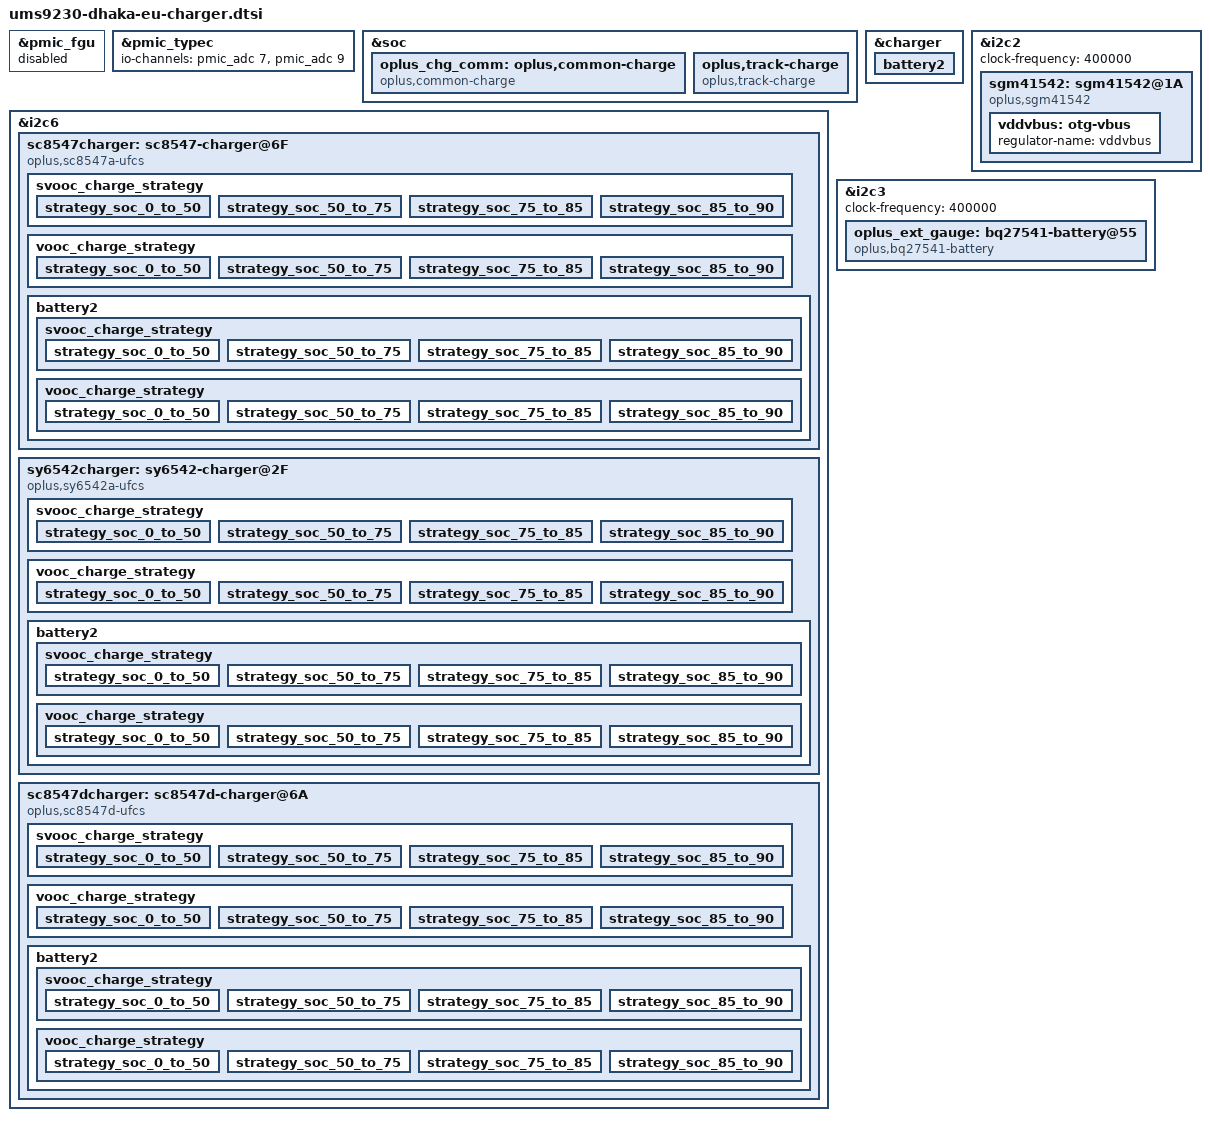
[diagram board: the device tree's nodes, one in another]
// SPDX-License-Identifier: GPL-2.0-only
/*
* Copyright (C) 2018-2020 Oplus. All rights reserved.
*/

&pmic_fgu {
	status = "disabled";
	//charger = <&sgm41542>;
	FUELGAGUE_APPLY = <(0)>;
	BATT_ID_FAST_CHECK = <(3)>;
	Enable_Is_Force_Full = <(1)>;
	sprd,calib-resistance-micro-ohms = <5000>;
	sprd,comp-resistance-mohm = <4>;
};

&pmic_typec {
	status = "okay";
	io-channels = <&pmic_adc 7>, <&pmic_adc 9>;
	io-channel-names = "cc1", "cc2";
};

&soc {
 	oplus_chg_comm: oplus,common-charge {
 		status = "ok";
 		compatible = "oplus,common-charge";

 		//io-channels = <&pmk8350_vadc PM8350_ADC7_AMUX_THM3_100K_PU>;
 		//io-channel-names = "pm8350_hot_pocket_therm";

 		//oplus,skin_temp_chan = "pm8350_hot_pocket_therm";

 		oplus,check-batt-full-by-sw;
 		oplus,fv-offset-voltage-mv = <32>;
 		oplus,sw-iterm-ma = <115>;
 		oplus,full-count-sw-num = <2>;
 		oplus,batt-uv-mv = <2500>;
 		oplus,batt-ov-mv = <4950>;
 		oplus,batt-oc-ma = <6500>;
 		oplus,batt-ovd-mv = <1000>;
 		oplus,batt-curr-limit-thr-mv = <4180>;

 		oplus,batt-them-thr = <(-20) 0 50 120 400 450 530>;//tbat
 		oplus,vbatmax-mv = <0 4470 4470 4470 4470 4470 4130 0>;//fv
 		oplus,vbatmax-mv_4p48 = <0 4470 4470 4470 4470 4470 4130 0>;//fv for 4p48 batt
 		oplus,ffc-temp-thr = <120 350 450>;
 		oplus,usb-ffc-step-max = <1>;
 		oplus,usb-ffc-fv-mv = <4500>;
 		oplus,usb-ffc-fv-cutoff-mv = <4600>;
 		oplus,usb-ffc-fcc-ma = <350 400>;
 		oplus,usb-ffc-fcc-cutoff-ma = <300 350>;
 	};
	oplus,track-charge {
		compatible = "oplus,track-charge";
		track,fast_chg_break_t_thd = <1000>;
		track,general_chg_break_t_thd = <200>;
		track,voocphy_type = <2>;
		track,wired_max_power = <45000>;
		track,wired_fast_chg_scheme = <4>;
		track,gauge_status_ctrl;
		track,nominal_qmax1 = <5166>;
		track,nominal_fcc1 = <4700>;
		track,external_gauge_num = <1>;
	};
 };
&charger {
	io-channels = <&pmic_adc 6>, <&pmic_adc 4>, <&pmic_adc 14>;
	io-channel-names = "usb_temp_v_l", "usb_temp_v_r", "charge_vbus";
	//for oplus chg framework:
	qcom,pd_input_current_charger_ma = <3000>;
	qcom,qc_input_current_charger_ma = <1500>;
	qcom,input_current_charger_ma = <2000>;
	qcom,input_current_usb_ma = <500>;
	qcom,input_current_cdp_ma = <1500>;
	qcom,input_current_camera_ma = <1200>;
	qcom,input_current_calling_ma = <1500>;

	qcom,led_warm_bat_decidegc = <350>;
	qcom,led_high_bat_decidegc = <370>;
	qcom,input_current_led_ma = <1200>;
	qcom,input_current_led_ma_high = <1200>;
	qcom,input_current_led_ma_warm = <1500>;
	qcom,input_current_led_ma_normal = <3000>;
	qcom,input_current_led_ma_forcmcc = <500>;
	qcom,input_current_led_ma_limit_high = <1200>;

	qcom,vooc_temp_bat_normal_decidegc = <350>;
	qcom,vooc_temp_bat_warm_decidegc = <370>;
	qcom,vooc_temp_bat_hot_decidegc = <440>;
	qcom,input_current_vooc_led_ma_high = <1200>;
	qcom,input_current_vooc_led_ma_warm = <1800>;
	qcom,input_current_vooc_led_ma_normal = <3600>;
	qcom,input_current_vooc_ma_normal = <3600>;
	qcom,input_current_vooc_ma_warm = <3200>;
	qcom,input_current_vooc_ma_high = <2200>;

	qcom,overtemp_bat_decidegc = <350>;
	qcom,iterm_disabled = <0>;
	//sw_full_count = <25>;
	qcom,iterm_ma = <302>;
	qcom,recharge-mv = <100>;

	qcom,batt_capacity_mah = <6000>; /*typical capacity*/
	//qcom,batt_capacity_mah = <4870>; /*rated capacity*/
	qcom,usb_high_than_bat_decidegc = <168>;

	qcom,removed_bat_decidegc = <390>;  /* < -39C */

	qcom,cold_bat_decidegc = <100>;  /* -10C ~ 0C */
	qcom,temp_cold_vfloat_mv = <4464>;
	qcom,temp_freeze_fastchg_current_ma_high = <1166>;
	qcom,temp_freeze_fastchg_current_ma_low = <874>;
	qcom,temp_freeze_fastchg_current_ma = <1166>;
	qcom,temp_cold_fastchg_current_ma_high = <1166>;
	qcom,temp_cold_fastchg_current_ma_low = <874>;
	qcom,temp_cold_fastchg_current_ma = <1166>;

	qcom,little_cold_bat_decidegc = <0>;    /* 0C ~ 5C */
	qcom,temp_little_cold_vfloat_mv = <4464>;
	qcom,temp_little_cold_fastchg_current_ma_high = <2200>;
	qcom,temp_little_cold_fastchg_current_ma_low = <2200>;
	qcom,temp_little_cold_fastchg_current_ma = <2200>;
	qcom,qc_temp_little_cold_fastchg_current_ma_high = <800>;
	qcom,qc_temp_little_cold_fastchg_current_ma_low = <2623>;
	qcom,pd_temp_little_cold_fastchg_current_ma_high = <3000>;
	qcom,pd_temp_little_cold_fastchg_current_ma_low = <2623>;

	qcom,cool_bat_decidegc = <50>;  /* 5C ~ 12C */
	qcom,temp_cool_vfloat_mv = <4464>;
	qcom,temp_cool_fastchg_current_ma_high = <2200>;
	qcom,temp_cool_fastchg_current_ma_low = <2200>;
	qcom,qc_temp_cool_fastchg_current_ma_high = <1600>;
	qcom,qc_temp_cool_fastchg_current_ma_low = <3000>;
	qcom,pd_temp_cool_fastchg_current_ma_high = <3000>;
	qcom,pd_temp_cool_fastchg_current_ma_low = <3000>;

	qcom,little_cool_bat_decidegc = <120>;  /* 12C ~ 16C */
	qcom,temp_little_cool_vfloat_mv = <4464>;
	qcom,temp_little_cool_fastchg_current_ma_high = <2200>;
	qcom,temp_little_cool_fastchg_current_ma_low = <2200>;
	qcom,temp_little_cool_fastchg_current_ma = <2200>;
	qcom,pd_temp_little_cool_fastchg_current_ma_high = <3000>;
	qcom,pd_temp_little_cool_fastchg_current_ma_low = <3000>;
	qcom,pd_temp_little_cool_fastchg_current_ma = <3000>;
	qcom,qc_temp_little_cool_fastchg_current_ma_high = <2200>;
	qcom,qc_temp_little_cool_fastchg_current_ma_low = <3000>;
	qcom,qc_temp_little_cool_fastchg_current_ma = <3000>;

	qcom,normal_bat_decidegc = <160>;       /* 16C ~ 45C */
	qcom,temp_normal_vfloat_mv = <4464>;
	qcom,temp_normal_fastchg_current_ma = <2200>;
	qcom,temp_normal_fastchg_current_ma_high = <2200>;
	qcom,temp_normal_fastchg_current_ma_low = <2200>;
	qcom,pd_temp_normal_fastchg_current_ma = <3000>;
	qcom,pd_temp_normal_fastchg_current_ma_high = <3000>;
	qcom,pd_temp_normal_fastchg_current_ma_low = <3000>;
	qcom,qc_temp_normal_fastchg_current_ma = <1500>;

	qcom,warm_bat_decidegc = <450>;         /* 45C ~ 53C */ /*8pin Bat Vooc project need add 3 degree C*/
	qcom,temp_warm_vfloat_mv = <4144>;
	qcom,temp_warm_fastchg_current_ma = <2200>;
	qcom,pd_temp_warm_fastchg_current_ma = <3000>;
	qcom,qc_temp_warm_fastchg_current_ma = <3000>;
	qcom,temp_warm_fastchg_current_ma_led_on = <1000>;

	qcom,hot_bat_decidegc = <530>;  /* > 53C */

	qcom,non_standard_vfloat_mv = <3980>;
	qcom,non_standard_fastchg_current_ma = <512>;

	qcom,short_c_bat_cv_mv = <4330>;
	qcom,short_c_bat_vfloat_mv = <3800>;
	qcom,short_c_bat_fastchg_current_ma = <512>;
	qcom,short_c_bat_vfloat_sw_limit = <3750>;

	qcom,cold_vfloat_sw_limit = <4415>;
	qcom,little_cold_vfloat_sw_limit = <4415>;
	qcom,cool_vfloat_sw_limit = <4415>;
	qcom,little_cool_vfloat_sw_limit = <4415>;
	qcom,normal_vfloat_sw_limit = <4415>;
	qcom,warm_vfloat_sw_limit = <4080>;
	qcom,non_standard_vfloat_sw_limit = <3930>;

	qcom,max_chg_time_sec = <72000>;
	qcom,charger_hv_thr = <10200>;
	qcom,charger_recv_thr = <10200>;
	qcom,charger_lv_thr = <3400>;
	qcom,vbatt_full_thr = <4465>;
	qcom,vbatt_hv_thr = <4600>;

	qcom,vfloat_step_mv = <32>;
	qcom,non_standard_vfloat_over_sw_limit = <3990>;
	qcom,cold_vfloat_over_sw_limit = <4475>;
	qcom,little_cold_vfloat_over_sw_limit = <4475>;
	qcom,cool_vfloat_over_sw_limit = <4475>;
	qcom,little_cool_vfloat_over_sw_limit = <4475>;
	qcom,normal_vfloat_over_sw_limit = <4475>;
	qcom,warm_vfloat_over_sw_limit = <4140>;

	qcom,vbatt_power_off = <3300>;
	qcom,vbatt_soc_1 = <3410>;
	qcom,vooc_project = <15>;
	qcom,vbatt_num = <1>;
	qcom,new_ui_warning_support;
	qcom,smart_charging_screenoff;
	oplus,smooth_switch_v2;
	oplus,reserve_chg_soc = <3>;
	oplus,reserve_dis_soc = <3>;
	qcom,smart_charge_version = <1>;

	qcom,normal_vterm_hw_inc = <18>;
	qcom,non_normal_vterm_hw_inc = <18>;
	qcom,usbtemp_batttemp_gap = <12>;

	qcom,ff1_normal_fastchg_ma = <1500>; /*12C~35c*/
	qcom,ff1_warm_fastchg_ma = <1500>;	/* 35C ~ 40c */
	qcom,ff1_exit_step_ma = <200>;
	qcom,ff1_warm_exit_step_ma = <200>;

	qcom,ffc2_normal_fastchg_ma = <750>;/*12C~35c*/
	qcom,ffc2_warm_fastchg_ma = <850>;	/* 35C ~ 40c */
	qcom,ffc2_temp_warm_decidegc = <350>;
	qcom,ffc2_temp_high_decidegc = <440>;
	qcom,ffc2_temp_low_decidegc = <120>;
	qcom,ffc2_exit_step_ma = <100>;
	qcom,ffc2_warm_exit_step_ma = <100>;

	qcom,ffc_normal_vfloat_sw_limit = <4495>;
	qcom,ffc_temp_normal_vfloat_mv = <4600>;
	qcom,ffc_normal_vfloat_over_sw_limit = <4600>;
	qcom,ffc_warm_vfloat_sw_limit = <4495>;

	qcom,ffc2_normal_vfloat_sw_limit = <4495>;
	qcom,ffc2_temp_normal_vfloat_mv = <4600>;
	qcom,ffc2_normal_vfloat_over_sw_limit = <4600>;
	qcom,ffc2_warm_vfloat_sw_limit = <4495>;


	qcom,default_iterm_ma = <302>;
	qcom,default_temp_normal_fastchg_current_ma = <2200>;
	qcom,default_normal_vfloat_sw_limit = <4420>;
	qcom,default_temp_normal_vfloat_mv = <4465>;
	qcom,default_normal_vfloat_over_sw_limit = <4475>;
	qcom,default_temp_little_cool_fastchg_current_ma = <2200>;
	qcom,default_little_cool_vfloat_sw_limit = <4415>;
	qcom,default_temp_little_cool_vfloat_mv = <4465>;
	qcom,default_little_cool_vfloat_over_sw_limit = <4475>;

	//for PD9V or QC9V
	qcom,vbatt_pdqc_to_5v_thr = <4500>;
	qcom,vbatt_pdqc_to_9v_thr = <4500>;

	//for control:
	qcom,cc_safeguard_enable;
	//qcom,suspend_after_full;
	qcom,check_batt_full_by_sw;
	qcom,chg_ctrl_by_lcd;
	qcom,dcp_screen_off_limit_switch;
	qcom,chg_ctrl_by_camera;
	qcom,chg_ctrl_by_calling;
	qcom,sw_vfloat_over_protect_enable;
	qcom,usbtemp_dischg_by_platpmic;
	qcom,support_usbtemp_protect_v2;
	qcom,ffc_support;
	qcom,chargerid_vol_disable;
	qcom,support_ntc_01c_precision;
	qcom,voocphy_support = <2>;
	//qcom,external_authenticate;
	qcom,chargerid_support;
	qcom,vooc_show_ui_soc_decimal;
	qcom,ui_soc_decimal_speedmin = <20>;//2A
	qcom,ccdetect_by_wd0;
	qcom,hvdcp_disabled; //turn off hvdcp func for doki
	//GPIO config:
	qcom,chargerid_switch-gpio = <&ap_gpio 175 0x00>;
	qcom,dischg-gpio = <&ap_gpio 11 0x00>;
	//qcom,ccdetect-gpio = <&ap_gpio 3 0x00>;
	qcom,support_abnormal_adapter;
	qcom,external_gauge;

	qcom,vooc-max-input-volt-support = <11000>;     //11V
	qcom,vooc-max-input-current-support = <4100>;   //4.1A

	oplus,support_hot_enter_kpoc;
	oplus,usbtemp_charging_current_limit = <2000>;
	oplus,poweroff_high_batt_temp = <720>;
	oplus,poweroff_emergency_batt_temp = <770>;
	oplus,usbtemp_batt_temp_over_hot = <60>;
	oplus,usbtemp_temp_gap_with_batt_temp_in_over_hot = <15>;
	qcom,external_gauge;
	qcom,smart_chg_soh_support;
	oplus,eco_common_support_region_list = <0x44>;
};

&i2c6 {
	status = "okay";
	clock-frequency = <400000>;
	#address-cells = <1>;
	#size-cells = <0>;
	dma-names = "no_rx_dma", "no_tx_dma";
	dmas = <&ap_dma 35 &ap_dma 36>;
	sc8547charger: sc8547-charger@6F{
		status = "okay";
		compatible = "oplus,sc8547a-ufcs";
		reg = <0x6F 0>;
		ocp_reg = <0xC>;
		ovp_reg = <0x36>;	/* 4.85V */

		qcom,remove_otg_en;

		qcom,irq_gpio = <&ap_gpio 126 0x00>;/*CP1_EINT*/
		qcom,external_gauge_support;
		interrupt-parent = <&ap_gpio>;
		interrupts = <126 0>;

		/*pinctrl-names = "switch1_act_switch2_act", "switch1_sleep_switch2_sleep",
					"charging_inter_active", "charging_inter_sleep";
		pinctrl-0 = <&charging_switch1_active>;
		pinctrl-1 = <&charging_switch1_sleep>;
		pinctrl-2 = <&charging_inter_active>;
		pinctrl-3 = <&charging_inter_sleep>;*/

		qcom,charging_switch1-gpio = <&ap_gpio 165 0x00>;

		qcom,copycat_vooc_support;
		/*qcom,voocphy_dual_cp_support;*/
		qcom,slave_cp_enable_thr = <1900>;		//2000-100mA
		qcom,slave_cp_disable_thr_high = <1600>;	//1500+100mA
		qcom,voocphy_current_default = <41>;

		qcom,svooc_cool_down_current_limit = <82 20 20 24 30 34 40 44 50 54 60 64 70 74 80>;
		qcom,vooc_cool_down_current_limit = <30 20 20 20 30 30 30 30 30 30 30 30 30 30 30>;
		qcom,abnormal_adapter_current = <41 41 40 40 30 30 20 20>;

		qcom,vooc_multistep_initial_batt_temp = <1000>;

		qcom,vooc_strategy_normal_current = <100>;
		qcom,vooc_normal_to_little_cool_current = <100>;
		qcom,vooc_batt_over_high_temp = <510>;

		qcom,vooc-low-temp = <0>;
		qcom,vooc-high-temp = <500>;
		qcom,vooc-low-soc = <0>;
		qcom,vooc-high-soc = <90>;
		qcom,vooc-warm-allow-vol = <4000>;
		qcom,vooc-warm-allow-soc = <50>;

		qcom,vooc_little_cold_temp = <50>;
		qcom,vooc_cool_temp = <120>;
		qcom,vooc_little_cool_temp = <200>;
		qcom,vooc_normal_low_temp = <350>;
		qcom,vooc-normal-high-temp = <440>;

		qcom,vooc_strategy1_batt_high_temp0 = <400>;
		qcom,vooc_strategy1_batt_high_temp1 = <420>;
		qcom,vooc_strategy1_batt_high_temp2 = <430>;
		qcom,vooc_strategy1_batt_low_temp2 = <420>;
		qcom,vooc_strategy1_batt_low_temp1 = <410>;
		qcom,vooc_strategy1_batt_low_temp0 = <390>;

		qcom,vooc_strategy1_high_current0 = <50>;
		qcom,vooc_strategy1_high_current1 = <40>;
		qcom,vooc_strategy1_high_current2 = <20>;
		qcom,vooc_strategy1_low_current2 = <40>;
		qcom,vooc_strategy1_low_current1 = <50>;
		qcom,vooc_strategy1_low_current0 = <60>;

		qcom,voocphy_freq_mincore = <1800000>;
		qcom,voocphy_freq_midcore = <1800000>;
		qcom,voocphy_freq_maxcore = <1800000>;
		qcom,voocphy_current_change_timeout = <100>;

		oplus,workaround_for_100w;

		qcom,voocphy_ibat_over_current = <8500>;
		qcom,voocphy_svooc_cp_max_ibus = <4500>;
		qcom,voocphy_vooc_cp_max_ibus = <3500>;
		qcom,voocphy_cp_max_ibus = <4500>;

		qcom,vooc_little_cold_full_voltage = <4150>;
		qcom,vooc_cool_full_voltage = <4500>;
		qcom,vooc_warm_full_voltage = <4130>;
		qcom,vooc_1time_full_voltage = <4500>;
		qcom,vooc_ntime_full_voltage = <4500>;
		qcom,low_curr_full_t1 = <120>;
		qcom,low_curr_full_t2 = <350>;
		qcom,low_curr_full_t3 = <440>;
		qcom,range1_low_curr_full = <750 4500
						705 4495
						660 4480
						615 4470
						570 4460>;
		qcom,range2_low_curr_full = <850 4500
						805 4495
						760 4480
						715 4470
						670 4460>;

		svooc_batt_sys_curve = <0 1 0 1 0 0 0	// 4000mA
					1 1 1 1 0 0 0	// 4604mV
					0 0 1 1 0 1 0	// 2600mA
					1 1 1 1 0 0 0	// 4604mV
					0 0 0 1 0 1 1	// 1100mA
					1 1 1 1 0 0 0>;	// 4604mV

		vooc_batt_sys_curve =  <0 1 0 1 0 0 0	// 4000mA
					1 1 1 1 0 0 0	// 4604mV
					0 0 1 1 0 1 0	// 2600mA
					1 1 1 1 0 0 0	// 4604mV
					0 0 0 1 0 1 1	// 1100mA
					1 1 1 1 0 0 0>;	// 4604mV

		svooc_charge_strategy {
			strategy_soc_0_to_50 {
				strategy_temp_little_cold =	<4140 13 0 0 0
								 4150 10 1 0 0>;
				strategy_temp_cool =	<4150 22 0 0 0
								 4460 22 0 0 0
								 4460 20 0 0 0
								 4460 15 0 0 0
								 4490 13 0 0 0
								 4500 10 1 0 0>;
				strategy_temp_little_cool =	<4150 22 0 0 0
								 4460 22 0 0 0
								 4460 20 0 0 0
								 4460 15 0 0 0
								 4490 13 0 0 0
								 4500 10 1 0 0>;
				strategy_temp_normal_low =	<4150 41 0 60 0
								 4150 30 0 1200 0
								 4230 27 0 0 0
								 4230 25 0 1200 0
								 4460 22 0 0 0
								 4460 20 0 0 0
								 4460 15 0 0 0
								 4490 13 0 0 0
								 4500 10 1 0 0>;
				strategy_temp_normal_high =	<4150 41 0 60 0
								 4150 30 0 1200 0
								 4230 27 0 0 0
								 4230 25 0 1200 0
								 4460 22 0 0 0
								 4460 20 0 0 0
								 4460 15 0 0 0
								 4490 13 0 0 0
								 4500 10 1 0 0>;
				strategy_temp_warm = <4120 16 0 0 0
								 4120 15 0 0 0
								 4130 10 1 0 0>;
			};

			strategy_soc_50_to_75 {
				strategy_temp_little_cold =	<4150 10 1 0 0>;
				strategy_temp_cool =	<4460 15 0 0 0
								 4490 13 0 0 0
								 4500 10 1 0 0>;
				strategy_temp_little_cool =	<4460 20 0 0 0
								 4460 15 0 0 0
								 4490 13 0 0 0
								 4500 10 1 0 0>;
				strategy_temp_normal_low =	<4230 25 0 0 0
								 4460 22 0 0 0
								 4460 20 0 0 0
								 4460 15 0 0 0
								 4490 13 0 0 0
								 4500 10 1 0 0>;
				strategy_temp_normal_high =	<4230 25 0 0 0
								 4460 22 0 0 0
								 4460 20 0 0 0
								 4460 15 0 0 0
								 4490 13 0 0 0
								 4500 10 1 0 0>;
				strategy_temp_warm = <4130 15 1 0 0>;
			};

			strategy_soc_75_to_85 {
				strategy_temp_little_cold =	<4150 10 1 0 0>;
				strategy_temp_cool =	<4500 10 1 0 0>;
				strategy_temp_little_cool =	<4460 15 0 0 0
								 4490 13 0 0 0
								 4500 10 1 0 0>;
				strategy_temp_normal_low =	<4460 15 0 0 0
								 4490 13 0 0 0
								 4500 10 1 0 0>;
				strategy_temp_normal_high =	<4460 15 0 0 0
								 4490 13 0 0 0
								 4500 10 1 0 0>;
				strategy_temp_warm = <4130 15 1 0 0>;
			};

			strategy_soc_85_to_90 {
				strategy_temp_little_cold =	<4150 10 1 0 0>;
				strategy_temp_cool =		<4500 10 1 0 0>;
				strategy_temp_little_cool =	<4500 10 1 0 0>;
				strategy_temp_normal_low =	<4500 10 1 0 0>;
				strategy_temp_normal_high =	<4500 10 1 0 0>;
				strategy_temp_warm = 		<4130 15 1 0 0>;
			};
		};

		vooc_charge_strategy {
			strategy_soc_0_to_50 {
				strategy_temp_little_cold =	<4140 26 0 0 0
								 4150 20 1 0 0>;			/*0-5C*/
				strategy_temp_cool =	<4460 30 0 0 0
								 4490 26 0 0 0
								 4500 20 1 0 0>;			/*5-12C*/
				strategy_temp_little_cool =	<4460 30 0 0 0
								 4490 26 0 0 0
								 4500 20 1 0 0>;			/*12-20C*/
				strategy_temp_normal_low =	<4460 30 0 0 0
								 4490 26 0 0 0
								 4500 20 1 0 0>;			/*20-35C*/
				strategy_temp_normal_high =	<4460 30 0 0 0
								 4490 26 0 0 0
								 4500 20 1 0 0>;			/*35C-44C*/
				strategy_temp_warm =		<4120 30 0 0 0
								 4130 20 1 0 0>;
			};

			strategy_soc_50_to_75 {
				strategy_temp_little_cold =	<4150 20 1 0 0>;
				strategy_temp_cool =	<4460 30 0 0 0
								 4490 26 0 0 0
								 4500 20 1 0 0>;
				strategy_temp_little_cool =	<4460 30 0 0 0
								 4490 26 0 0 0
								 4500 20 1 0 0>;
				strategy_temp_normal_low =	<4460 30 0 0 0
								 4490 26 0 0 0
								 4500 20 1 0 0>;
				strategy_temp_normal_high =	<4460 30 0 0 0
								 4490 26 0 0 0
								 4500 20 1 0 0>;
				strategy_temp_warm = <4130 30 1 0 0>;
			};

			strategy_soc_75_to_85 {
				strategy_temp_little_cold =	<4150 20 1 0 0>;
				strategy_temp_cool =	<4500 20 1 0 0>;
				strategy_temp_little_cool =	<4460 30 0 0 0
								 4490 26 0 0 0
								 4500 20 1 0 0>;
				strategy_temp_normal_low =	<4460 30 0 0 0
								 4490 26 0 0 0
								 4500 20 1 0 0>;
				strategy_temp_normal_high =	<4460 30 0 0 0
								 4490 26 0 0 0
								 4500 20 1 0 0>;
				strategy_temp_warm = <4130 30 1 0 0>;
			};

			strategy_soc_85_to_90 {
				strategy_temp_little_cold =	<4150 20 1 0 0>;
				strategy_temp_cool =		<4500 20 1 0 0>;
				strategy_temp_little_cool =	<4500 20 1 0 0>;
				strategy_temp_normal_low =	<4500 20 1 0 0>;
				strategy_temp_normal_high =	<4500 20 1 0 0>;
				strategy_temp_warm = 		<4130 30 1 0 0>;
			};
		};
	};
	sy6542charger: sy6542-charger@2F{
		status = "okay";
		compatible = "oplus,sy6542a-ufcs";
		reg = <0x2F 0>;
		ocp_reg = <0xC>;
		ovp_reg = <0x36>;	/* 4.85V */

		qcom,remove_otg_en;

		qcom,irq_gpio = <&ap_gpio 126 0x00>;/*CP1_EINT*/
		qcom,external_gauge_support;
		interrupt-parent = <&ap_gpio>;
		interrupts = <126 0>;

		/*pinctrl-names = "switch1_act_switch2_act", "switch1_sleep_switch2_sleep",
					"charging_inter_active", "charging_inter_sleep";
		pinctrl-0 = <&charging_switch1_active>;
		pinctrl-1 = <&charging_switch1_sleep>;
		pinctrl-2 = <&charging_inter_active>;
		pinctrl-3 = <&charging_inter_sleep>;*/

		qcom,charging_switch1-gpio = <&ap_gpio 165 0x00>;

		qcom,copycat_vooc_support;
		/*qcom,voocphy_dual_cp_support;*/
		qcom,slave_cp_enable_thr = <1900>;		//2000-100mA
		qcom,slave_cp_disable_thr_high = <1600>;	//1500+100mA
		qcom,voocphy_current_default = <41>;

		qcom,svooc_cool_down_current_limit = <82 20 20 24 30 34 40 44 50 54 60 64 70 74 80>;
		qcom,vooc_cool_down_current_limit = <30 20 20 20 30 30 30 30 30 30 30 30 30 30 30>;
		qcom,abnormal_adapter_current = <41 41 40 40 30 30 20 20>;

		qcom,vooc_multistep_initial_batt_temp = <1000>;

		qcom,vooc_strategy_normal_current = <100>;
		qcom,vooc_normal_to_little_cool_current = <100>;
		qcom,vooc_batt_over_high_temp = <510>;

		qcom,vooc-low-temp = <0>;
		qcom,vooc-high-temp = <500>;
		qcom,vooc-low-soc = <0>;
		qcom,vooc-high-soc = <90>;
		qcom,vooc-warm-allow-vol = <4000>;
		qcom,vooc-warm-allow-soc = <50>;

		qcom,vooc_little_cold_temp = <50>;
		qcom,vooc_cool_temp = <120>;
		qcom,vooc_little_cool_temp = <200>;
		qcom,vooc_normal_low_temp = <350>;
		qcom,vooc-normal-high-temp = <440>;

		qcom,vooc_strategy1_batt_high_temp0 = <400>;
		qcom,vooc_strategy1_batt_high_temp1 = <420>;
		qcom,vooc_strategy1_batt_high_temp2 = <430>;
		qcom,vooc_strategy1_batt_low_temp2 = <420>;
		qcom,vooc_strategy1_batt_low_temp1 = <410>;
		qcom,vooc_strategy1_batt_low_temp0 = <390>;

		qcom,vooc_strategy1_high_current0 = <50>;
		qcom,vooc_strategy1_high_current1 = <40>;
		qcom,vooc_strategy1_high_current2 = <20>;
		qcom,vooc_strategy1_low_current2 = <40>;
		qcom,vooc_strategy1_low_current1 = <50>;
		qcom,vooc_strategy1_low_current0 = <60>;

		qcom,voocphy_freq_mincore = <1800000>;
		qcom,voocphy_freq_midcore = <1800000>;
		qcom,voocphy_freq_maxcore = <1800000>;
		qcom,voocphy_current_change_timeout = <100>;

		oplus,workaround_for_100w;

		qcom,voocphy_ibat_over_current = <8500>;
		qcom,voocphy_svooc_cp_max_ibus = <4500>;
		qcom,voocphy_vooc_cp_max_ibus = <3500>;
		qcom,voocphy_cp_max_ibus = <4500>;

		qcom,vooc_little_cold_full_voltage = <4150>;
		qcom,vooc_cool_full_voltage = <4500>;
		qcom,vooc_warm_full_voltage = <4130>;
		qcom,vooc_1time_full_voltage = <4500>;
		qcom,vooc_ntime_full_voltage = <4500>;
		qcom,low_curr_full_t1 = <120>;
		qcom,low_curr_full_t2 = <350>;
		qcom,low_curr_full_t3 = <440>;
		qcom,range1_low_curr_full = <750 4500
						705 4495
						660 4480
						615 4470
						570 4460>;
		qcom,range2_low_curr_full = <850 4500
						805 4495
						760 4480
						715 4470
						670 4460>;

		svooc_batt_sys_curve = <0 1 0 1 0 0 0	// 4000mA
					1 1 1 1 0 0 0	// 4604mV
					0 0 1 1 0 1 0	// 2600mA
					1 1 1 1 0 0 0	// 4604mV
					0 0 0 1 0 1 1	// 1100mA
					1 1 1 1 0 0 0>;	// 4604mV

		vooc_batt_sys_curve =  <0 1 0 1 0 0 0	// 4000mA
					1 1 1 1 0 0 0	// 4604mV
					0 0 1 1 0 1 0	// 2600mA
					1 1 1 1 0 0 0	// 4604mV
					0 0 0 1 0 1 1	// 1100mA
					1 1 1 1 0 0 0>;	// 4604mV

		svooc_charge_strategy {
			strategy_soc_0_to_50 {
				strategy_temp_little_cold =	<4140 13 0 0 0
								 4150 10 1 0 0>;
				strategy_temp_cool =	<4150 22 0 0 0
								 4460 22 0 0 0
								 4460 20 0 0 0
								 4460 15 0 0 0
								 4490 13 0 0 0
								 4500 10 1 0 0>;
				strategy_temp_little_cool =	<4150 22 0 0 0
								 4460 22 0 0 0
								 4460 20 0 0 0
								 4460 15 0 0 0
								 4490 13 0 0 0
								 4500 10 1 0 0>;
				strategy_temp_normal_low =	<4150 41 0 60 0
								 4150 30 0 1200 0
								 4230 27 0 0 0
								 4230 25 0 1200 0
								 4460 22 0 0 0
								 4460 20 0 0 0
								 4460 15 0 0 0
								 4490 13 0 0 0
								 4500 10 1 0 0>;
				strategy_temp_normal_high =	<4150 41 0 60 0
								 4150 30 0 1200 0
								 4230 27 0 0 0
								 4230 25 0 1200 0
								 4460 22 0 0 0
								 4460 20 0 0 0
								 4460 15 0 0 0
								 4490 13 0 0 0
								 4500 10 1 0 0>;
				strategy_temp_warm = <4120 16 0 0 0
								 4120 15 0 0 0
								 4130 10 1 0 0>;
			};

			strategy_soc_50_to_75 {
				strategy_temp_little_cold =	<4150 10 1 0 0>;
				strategy_temp_cool =	<4460 15 0 0 0
								 4490 13 0 0 0
								 4500 10 1 0 0>;
				strategy_temp_little_cool =	<4460 20 0 0 0
								 4460 15 0 0 0
								 4490 13 0 0 0
								 4500 10 1 0 0>;
				strategy_temp_normal_low =	<4230 25 0 0 0
								 4460 22 0 0 0
								 4460 20 0 0 0
								 4460 15 0 0 0
								 4490 13 0 0 0
								 4500 10 1 0 0>;
				strategy_temp_normal_high =	<4230 25 0 0 0
								 4460 22 0 0 0
								 4460 20 0 0 0
								 4460 15 0 0 0
								 4490 13 0 0 0
								 4500 10 1 0 0>;
				strategy_temp_warm = <4130 15 1 0 0>;
			};

			strategy_soc_75_to_85 {
				strategy_temp_little_cold =	<4150 10 1 0 0>;
				strategy_temp_cool =	<4500 10 1 0 0>;
				strategy_temp_little_cool =	<4460 15 0 0 0
								 4490 13 0 0 0
								 4500 10 1 0 0>;
				strategy_temp_normal_low =	<4460 15 0 0 0
								 4490 13 0 0 0
								 4500 10 1 0 0>;
				strategy_temp_normal_high =	<4460 15 0 0 0
								 4490 13 0 0 0
								 4500 10 1 0 0>;
				strategy_temp_warm = <4130 15 1 0 0>;
			};

			strategy_soc_85_to_90 {
				strategy_temp_little_cold =	<4150 10 1 0 0>;
				strategy_temp_cool =		<4500 10 1 0 0>;
				strategy_temp_little_cool =	<4500 10 1 0 0>;
				strategy_temp_normal_low =	<4500 10 1 0 0>;
				strategy_temp_normal_high =	<4500 10 1 0 0>;
				strategy_temp_warm = 		<4130 15 1 0 0>;
			};
		};

		vooc_charge_strategy {
			strategy_soc_0_to_50 {
				strategy_temp_little_cold =	<4140 26 0 0 0
								 4150 20 1 0 0>;			/*0-5C*/
				strategy_temp_cool =	<4460 30 0 0 0
								 4490 26 0 0 0
								 4500 20 1 0 0>;			/*5-12C*/
				strategy_temp_little_cool =	<4460 30 0 0 0
								 4490 26 0 0 0
								 4500 20 1 0 0>;			/*12-20C*/
				strategy_temp_normal_low =	<4460 30 0 0 0
								 4490 26 0 0 0
								 4500 20 1 0 0>;			/*20-35C*/
				strategy_temp_normal_high =	<4460 30 0 0 0
								 4490 26 0 0 0
								 4500 20 1 0 0>;			/*35C-44C*/
				strategy_temp_warm =		<4120 30 0 0 0
								 4130 20 1 0 0>;
			};

			strategy_soc_50_to_75 {
				strategy_temp_little_cold =	<4150 20 1 0 0>;
				strategy_temp_cool =	<4460 30 0 0 0
								 4490 26 0 0 0
								 4500 20 1 0 0>;
				strategy_temp_little_cool =	<4460 30 0 0 0
								 4490 26 0 0 0
								 4500 20 1 0 0>;
				strategy_temp_normal_low =	<4460 30 0 0 0
								 4490 26 0 0 0
								 4500 20 1 0 0>;
				strategy_temp_normal_high =	<4460 30 0 0 0
								 4490 26 0 0 0
								 4500 20 1 0 0>;
				strategy_temp_warm = <4130 30 1 0 0>;
			};

			strategy_soc_75_to_85 {
				strategy_temp_little_cold =	<4150 20 1 0 0>;
				strategy_temp_cool =	<4500 20 1 0 0>;
				strategy_temp_little_cool =	<4460 30 0 0 0
								 4490 26 0 0 0
								 4500 20 1 0 0>;
				strategy_temp_normal_low =	<4460 30 0 0 0
								 4490 26 0 0 0
								 4500 20 1 0 0>;
				strategy_temp_normal_high =	<4460 30 0 0 0
								 4490 26 0 0 0
								 4500 20 1 0 0>;
				strategy_temp_warm = <4130 30 1 0 0>;
			};

			strategy_soc_85_to_90 {
				strategy_temp_little_cold =	<4150 20 1 0 0>;
				strategy_temp_cool =		<4500 20 1 0 0>;
				strategy_temp_little_cool =	<4500 20 1 0 0>;
				strategy_temp_normal_low =	<4500 20 1 0 0>;
				strategy_temp_normal_high =	<4500 20 1 0 0>;
				strategy_temp_warm = 		<4130 30 1 0 0>;
			};
		};
	};
	sc8547dcharger: sc8547d-charger@6A{
		status = "okay";
		compatible = "oplus,sc8547d-ufcs";
		reg = <0x6A 0>;
		ocp_reg = <0xC>;
		ovp_reg = <0x36>;	/* 4.85V */

		qcom,remove_otg_en;

		qcom,irq_gpio = <&ap_gpio 126 0x00>;/*CP1_EINT*/
		qcom,external_gauge_support;
		interrupt-parent = <&ap_gpio>;
		interrupts = <126 0>;

		/*pinctrl-names = "switch1_act_switch2_act", "switch1_sleep_switch2_sleep",
					"charging_inter_active", "charging_inter_sleep";
		pinctrl-0 = <&charging_switch1_active>;
		pinctrl-1 = <&charging_switch1_sleep>;
		pinctrl-2 = <&charging_inter_active>;
		pinctrl-3 = <&charging_inter_sleep>;*/

		qcom,charging_switch1-gpio = <&ap_gpio 165 0x00>;

		qcom,copycat_vooc_support;
		/*qcom,voocphy_dual_cp_support;*/
		qcom,slave_cp_enable_thr = <1900>;		//2000-100mA
		qcom,slave_cp_disable_thr_high = <1600>;	//1500+100mA
		qcom,voocphy_current_default = <41>;

		qcom,svooc_cool_down_current_limit = <82 20 20 24 30 34 40 44 50 54 60 64 70 74 80>;
		qcom,vooc_cool_down_current_limit = <30 20 20 20 30 30 30 30 30 30 30 30 30 30 30>;
		qcom,abnormal_adapter_current = <41 41 40 40 30 30 20 20>;

		qcom,vooc_multistep_initial_batt_temp = <1000>;

		qcom,vooc_strategy_normal_current = <100>;
		qcom,vooc_normal_to_little_cool_current = <100>;
		qcom,vooc_batt_over_high_temp = <510>;

		qcom,vooc-low-temp = <0>;
		qcom,vooc-high-temp = <500>;
		qcom,vooc-low-soc = <0>;
		qcom,vooc-high-soc = <90>;
		qcom,vooc-warm-allow-vol = <4000>;
		qcom,vooc-warm-allow-soc = <50>;

		qcom,vooc_little_cold_temp = <50>;
		qcom,vooc_cool_temp = <120>;
		qcom,vooc_little_cool_temp = <200>;
		qcom,vooc_normal_low_temp = <350>;
		qcom,vooc-normal-high-temp = <440>;

		qcom,vooc_strategy1_batt_high_temp0 = <400>;
		qcom,vooc_strategy1_batt_high_temp1 = <420>;
		qcom,vooc_strategy1_batt_high_temp2 = <430>;
		qcom,vooc_strategy1_batt_low_temp2 = <420>;
		qcom,vooc_strategy1_batt_low_temp1 = <410>;
		qcom,vooc_strategy1_batt_low_temp0 = <390>;

		qcom,vooc_strategy1_high_current0 = <50>;
		qcom,vooc_strategy1_high_current1 = <40>;
		qcom,vooc_strategy1_high_current2 = <20>;
		qcom,vooc_strategy1_low_current2 = <40>;
		qcom,vooc_strategy1_low_current1 = <50>;
		qcom,vooc_strategy1_low_current0 = <60>;

		qcom,voocphy_freq_mincore = <1800000>;
		qcom,voocphy_freq_midcore = <1800000>;
		qcom,voocphy_freq_maxcore = <1800000>;
		qcom,voocphy_current_change_timeout = <100>;

		oplus,workaround_for_100w;

		qcom,voocphy_ibat_over_current = <8500>;
		qcom,voocphy_svooc_cp_max_ibus = <4500>;
		qcom,voocphy_vooc_cp_max_ibus = <3500>;
		qcom,voocphy_cp_max_ibus = <4500>;

		qcom,vooc_little_cold_full_voltage = <4150>;
		qcom,vooc_cool_full_voltage = <4500>;
		qcom,vooc_warm_full_voltage = <4130>;
		qcom,vooc_1time_full_voltage = <4500>;
		qcom,vooc_ntime_full_voltage = <4500>;
		qcom,low_curr_full_t1 = <120>;
		qcom,low_curr_full_t2 = <350>;
		qcom,low_curr_full_t3 = <440>;
		qcom,range1_low_curr_full = <750 4500
						705 4495
						660 4480
						615 4470
						570 4460>;
		qcom,range2_low_curr_full = <850 4500
						805 4495
						760 4480
						715 4470
						670 4460>;

		svooc_batt_sys_curve = <0 1 0 1 0 0 0	// 4000mA
					1 1 1 1 0 0 0	// 4604mV
					0 0 1 1 0 1 0	// 2600mA
					1 1 1 1 0 0 0	// 4604mV
					0 0 0 1 0 1 1	// 1100mA
					1 1 1 1 0 0 0>;	// 4604mV

		vooc_batt_sys_curve =  <0 1 0 1 0 0 0	// 4000mA
					1 1 1 1 0 0 0	// 4604mV
					0 0 1 1 0 1 0	// 2600mA
					1 1 1 1 0 0 0	// 4604mV
					0 0 0 1 0 1 1	// 1100mA
					1 1 1 1 0 0 0>;	// 4604mV

		svooc_charge_strategy {
			strategy_soc_0_to_50 {
				strategy_temp_little_cold =	<4140 13 0 0 0
								 4150 10 1 0 0>;
				strategy_temp_cool =	<4150 22 0 0 0
								 4460 22 0 0 0
								 4460 20 0 0 0
								 4460 15 0 0 0
								 4490 13 0 0 0
								 4500 10 1 0 0>;
				strategy_temp_little_cool =	<4150 22 0 0 0
								 4460 22 0 0 0
								 4460 20 0 0 0
								 4460 15 0 0 0
								 4490 13 0 0 0
								 4500 10 1 0 0>;
				strategy_temp_normal_low =	<4150 41 0 60 0
								 4150 30 0 1200 0
								 4230 27 0 0 0
								 4230 25 0 1200 0
								 4460 22 0 0 0
								 4460 20 0 0 0
								 4460 15 0 0 0
								 4490 13 0 0 0
								 4500 10 1 0 0>;
				strategy_temp_normal_high =	<4150 41 0 60 0
								 4150 30 0 1200 0
								 4230 27 0 0 0
								 4230 25 0 1200 0
								 4460 22 0 0 0
								 4460 20 0 0 0
								 4460 15 0 0 0
								 4490 13 0 0 0
								 4500 10 1 0 0>;
				strategy_temp_warm = <4120 16 0 0 0
								 4120 15 0 0 0
								 4130 10 1 0 0>;
			};

			strategy_soc_50_to_75 {
				strategy_temp_little_cold =	<4150 10 1 0 0>;
				strategy_temp_cool =	<4460 15 0 0 0
								 4490 13 0 0 0
								 4500 10 1 0 0>;
				strategy_temp_little_cool =	<4460 20 0 0 0
								 4460 15 0 0 0
								 4490 13 0 0 0
								 4500 10 1 0 0>;
				strategy_temp_normal_low =	<4230 25 0 0 0
								 4460 22 0 0 0
								 4460 20 0 0 0
								 4460 15 0 0 0
								 4490 13 0 0 0
								 4500 10 1 0 0>;
				strategy_temp_normal_high =	<4230 25 0 0 0
								 4460 22 0 0 0
								 4460 20 0 0 0
								 4460 15 0 0 0
								 4490 13 0 0 0
								 4500 10 1 0 0>;
				strategy_temp_warm = <4130 15 1 0 0>;
			};

			strategy_soc_75_to_85 {
				strategy_temp_little_cold =	<4150 10 1 0 0>;
				strategy_temp_cool =	<4500 10 1 0 0>;
				strategy_temp_little_cool =	<4460 15 0 0 0
								 4490 13 0 0 0
								 4500 10 1 0 0>;
				strategy_temp_normal_low =	<4460 15 0 0 0
								 4490 13 0 0 0
								 4500 10 1 0 0>;
				strategy_temp_normal_high =	<4460 15 0 0 0
								 4490 13 0 0 0
								 4500 10 1 0 0>;
				strategy_temp_warm = <4130 15 1 0 0>;
			};

			strategy_soc_85_to_90 {
				strategy_temp_little_cold =	<4150 10 1 0 0>;
				strategy_temp_cool =		<4500 10 1 0 0>;
				strategy_temp_little_cool =	<4500 10 1 0 0>;
				strategy_temp_normal_low =	<4500 10 1 0 0>;
				strategy_temp_normal_high =	<4500 10 1 0 0>;
				strategy_temp_warm = 		<4130 15 1 0 0>;
			};
		};

		vooc_charge_strategy {
			strategy_soc_0_to_50 {
				strategy_temp_little_cold =	<4140 26 0 0 0
								 4150 20 1 0 0>;			/*0-5C*/
				strategy_temp_cool =	<4460 30 0 0 0
								 4490 26 0 0 0
								 4500 20 1 0 0>;			/*5-12C*/
				strategy_temp_little_cool =	<4460 30 0 0 0
								 4490 26 0 0 0
								 4500 20 1 0 0>;			/*12-20C*/
				strategy_temp_normal_low =	<4460 30 0 0 0
								 4490 26 0 0 0
								 4500 20 1 0 0>;			/*20-35C*/
				strategy_temp_normal_high =	<4460 30 0 0 0
								 4490 26 0 0 0
								 4500 20 1 0 0>;			/*35C-44C*/
				strategy_temp_warm =		<4120 30 0 0 0
								 4130 20 1 0 0>;
			};

			strategy_soc_50_to_75 {
				strategy_temp_little_cold =	<4150 20 1 0 0>;
				strategy_temp_cool =	<4460 30 0 0 0
								 4490 26 0 0 0
								 4500 20 1 0 0>;
				strategy_temp_little_cool =	<4460 30 0 0 0
								 4490 26 0 0 0
								 4500 20 1 0 0>;
				strategy_temp_normal_low =	<4460 30 0 0 0
								 4490 26 0 0 0
								 4500 20 1 0 0>;
				strategy_temp_normal_high =	<4460 30 0 0 0
								 4490 26 0 0 0
								 4500 20 1 0 0>;
				strategy_temp_warm = <4130 30 1 0 0>;
			};

			strategy_soc_75_to_85 {
				strategy_temp_little_cold =	<4150 20 1 0 0>;
				strategy_temp_cool =	<4500 20 1 0 0>;
				strategy_temp_little_cool =	<4460 30 0 0 0
								 4490 26 0 0 0
								 4500 20 1 0 0>;
				strategy_temp_normal_low =	<4460 30 0 0 0
								 4490 26 0 0 0
								 4500 20 1 0 0>;
				strategy_temp_normal_high =	<4460 30 0 0 0
								 4490 26 0 0 0
								 4500 20 1 0 0>;
				strategy_temp_warm = <4130 30 1 0 0>;
			};

			strategy_soc_85_to_90 {
				strategy_temp_little_cold =	<4150 20 1 0 0>;
				strategy_temp_cool =		<4500 20 1 0 0>;
				strategy_temp_little_cool =	<4500 20 1 0 0>;
				strategy_temp_normal_low =	<4500 20 1 0 0>;
				strategy_temp_normal_high =	<4500 20 1 0 0>;
				strategy_temp_warm = 		<4130 30 1 0 0>;
			};
		};
	};
};

&charger {
	battery2 {
		io-channels = <&pmic_adc 6>, <&pmic_adc 4>, <&pmic_adc 14>;
		io-channel-names = "usb_temp_v_l", "usb_temp_v_r", "charge_vbus";
		//for oplus chg framework:
		qcom,pd_input_current_charger_ma = <3000>;
		qcom,qc_input_current_charger_ma = <1500>;
		qcom,input_current_charger_ma = <2000>;
		qcom,input_current_usb_ma = <500>;
		qcom,input_current_cdp_ma = <1500>;
		qcom,input_current_camera_ma = <1200>;
		qcom,input_current_calling_ma = <1500>;

		qcom,led_warm_bat_decidegc = <350>;
		qcom,led_high_bat_decidegc = <370>;
		qcom,input_current_led_ma = <1200>;
		qcom,input_current_led_ma_high = <1200>;
		qcom,input_current_led_ma_warm = <1500>;
		qcom,input_current_led_ma_normal = <3000>;
		qcom,input_current_led_ma_forcmcc = <500>;
		qcom,input_current_led_ma_limit_high = <1200>;

		qcom,vooc_temp_bat_normal_decidegc = <350>;
		qcom,vooc_temp_bat_warm_decidegc = <370>;
		qcom,vooc_temp_bat_hot_decidegc = <440>;
		qcom,input_current_vooc_led_ma_high = <1200>;
		qcom,input_current_vooc_led_ma_warm = <1800>;
		qcom,input_current_vooc_led_ma_normal = <3600>;
		qcom,input_current_vooc_ma_normal = <3600>;
		qcom,input_current_vooc_ma_warm = <3200>;
		qcom,input_current_vooc_ma_high = <2200>;

		qcom,overtemp_bat_decidegc = <350>;
		qcom,iterm_disabled = <0>;
		//sw_full_count = <25>;
		qcom,iterm_ma = <302>;
		qcom,recharge-mv = <100>;

		qcom,batt_capacity_mah = <6000>; /*typical capacity*/
		//qcom,batt_capacity_mah = <4870>; /*rated capacity*/
		qcom,usb_high_than_bat_decidegc = <168>;

		qcom,removed_bat_decidegc = <390>;  /* < -39C */

		qcom,cold_bat_decidegc = <100>;  /* -10C ~ 0C */
		qcom,temp_cold_vfloat_mv = <4464>;
		qcom,temp_freeze_fastchg_current_ma_high = <1166>;
		qcom,temp_freeze_fastchg_current_ma_low = <874>;
		qcom,temp_freeze_fastchg_current_ma = <1166>;
		qcom,temp_cold_fastchg_current_ma_high = <1166>;
		qcom,temp_cold_fastchg_current_ma_low = <874>;
		qcom,temp_cold_fastchg_current_ma = <1166>;
		qcom,qc_temp_freeze_fastchg_current_ma_high = <300>;
		qcom,qc_temp_freeze_fastchg_current_ma_low = <874>;
		qcom,pd_temp_freeze_fastchg_current_ma_high = <1166>;
		qcom,pd_temp_freeze_fastchg_current_ma_low = <874>;

		qcom,little_cold_bat_decidegc = <0>;    /* 0C ~ 5C */
		qcom,temp_little_cold_vfloat_mv = <4464>;
		qcom,temp_little_cold_fastchg_current_ma_high = <2200>;
		qcom,temp_little_cold_fastchg_current_ma_low = <2200>;
		qcom,temp_little_cold_fastchg_current_ma = <2200>;
		qcom,qc_temp_little_cold_fastchg_current_ma_high = <800>;
		qcom,qc_temp_little_cold_fastchg_current_ma_low = <2623>;
		qcom,pd_temp_little_cold_fastchg_current_ma_high = <3000>;
		qcom,pd_temp_little_cold_fastchg_current_ma_low = <2623>;

		qcom,cool_bat_decidegc = <50>;  /* 5C ~ 12C */
		qcom,temp_cool_vfloat_mv = <4464>;
		qcom,temp_cool_fastchg_current_ma_high = <2200>;
		qcom,temp_cool_fastchg_current_ma_low = <2200>;
		qcom,qc_temp_cool_fastchg_current_ma_high = <1600>;
		qcom,qc_temp_cool_fastchg_current_ma_low = <3000>;
		qcom,pd_temp_cool_fastchg_current_ma_high = <3000>;
		qcom,pd_temp_cool_fastchg_current_ma_low = <3000>;

		qcom,little_cool_bat_decidegc = <120>;  /* 12C ~ 16C */
		qcom,temp_little_cool_vfloat_mv = <4464>;
		qcom,temp_little_cool_fastchg_current_ma_high = <2200>;
		qcom,temp_little_cool_fastchg_current_ma_low = <2200>;
		qcom,temp_little_cool_fastchg_current_ma = <2200>;
		qcom,pd_temp_little_cool_fastchg_current_ma_high = <3000>;
		qcom,pd_temp_little_cool_fastchg_current_ma_low = <3000>;
		qcom,pd_temp_little_cool_fastchg_current_ma = <3000>;
		qcom,qc_temp_little_cool_fastchg_current_ma_high = <2200>;
		qcom,qc_temp_little_cool_fastchg_current_ma_low = <3000>;
		qcom,qc_temp_little_cool_fastchg_current_ma = <3000>;

		qcom,normal_bat_decidegc = <160>;       /* 16C ~ 45C */
		qcom,temp_normal_vfloat_mv = <4464>;
		qcom,temp_normal_fastchg_current_ma = <2200>;
		qcom,temp_normal_fastchg_current_ma_high = <2200>;
		qcom,temp_normal_fastchg_current_ma_low = <2200>;
		qcom,pd_temp_normal_fastchg_current_ma = <3000>;
		qcom,pd_temp_normal_fastchg_current_ma_high = <3000>;
		qcom,pd_temp_normal_fastchg_current_ma_low = <3000>;
		qcom,qc_temp_normal_fastchg_current_ma_high = <2200>;
		qcom,qc_temp_normal_fastchg_current_ma_low = <3000>;
		qcom,qc_temp_normal_fastchg_current_ma = <3000>;

		qcom,warm_bat_decidegc = <450>;         /* 45C ~ 53C */ /*8pin Bat Vooc project need add 3 degree C*/
		qcom,temp_warm_vfloat_mv = <4144>;
		qcom,temp_warm_fastchg_current_ma = <2200>;
		qcom,pd_temp_warm_fastchg_current_ma = <3000>;
		qcom,qc_temp_warm_fastchg_current_ma = <3000>;
		qcom,temp_warm_fastchg_current_ma_led_on = <1000>;

		qcom,hot_bat_decidegc = <530>;  /* > 53C */

		qcom,non_standard_vfloat_mv = <3980>;
		qcom,non_standard_fastchg_current_ma = <512>;

		qcom,short_c_bat_cv_mv = <4330>;
		qcom,short_c_bat_vfloat_mv = <3800>;
		qcom,short_c_bat_fastchg_current_ma = <512>;
		qcom,short_c_bat_vfloat_sw_limit = <3750>;

		qcom,cold_vfloat_sw_limit = <4415>;
		qcom,little_cold_vfloat_sw_limit = <4415>;
		qcom,cool_vfloat_sw_limit = <4415>;
		qcom,little_cool_vfloat_sw_limit = <4415>;
		qcom,normal_vfloat_sw_limit = <4415>;
		qcom,warm_vfloat_sw_limit = <4080>;
		qcom,non_standard_vfloat_sw_limit = <3930>;

		qcom,max_chg_time_sec = <72000>;
		qcom,charger_hv_thr = <10200>;
		qcom,charger_recv_thr = <10200>;
		qcom,charger_lv_thr = <3400>;
		qcom,vbatt_full_thr = <4465>;
		qcom,vbatt_hv_thr = <4600>;

		qcom,vfloat_step_mv = <32>;
		qcom,non_standard_vfloat_over_sw_limit = <3990>;
		qcom,cold_vfloat_over_sw_limit = <4475>;
		qcom,little_cold_vfloat_over_sw_limit = <4475>;
		qcom,cool_vfloat_over_sw_limit = <4475>;
		qcom,little_cool_vfloat_over_sw_limit = <4475>;
		qcom,normal_vfloat_over_sw_limit = <4475>;
		qcom,warm_vfloat_over_sw_limit = <4140>;

		qcom,vbatt_power_off = <3300>;
		qcom,vbatt_soc_1 = <3410>;
		qcom,vooc_project = <15>;
		qcom,vbatt_num = <1>;
		qcom,new_ui_warning_support;
		qcom,smart_charging_screenoff;
		oplus,smooth_switch_v2;
		oplus,reserve_chg_soc = <3>;
		oplus,reserve_dis_soc = <3>;
		qcom,smart_charge_version = <1>;

		qcom,normal_vterm_hw_inc = <18>;
		qcom,non_normal_vterm_hw_inc = <18>;
		qcom,usbtemp_batttemp_gap = <12>;

		qcom,ff1_normal_fastchg_ma = <1500>; /*12C~35c*/
		qcom,ff1_warm_fastchg_ma = <1500>;	/* 35C ~ 40c */
		qcom,ff1_exit_step_ma = <200>;
		qcom,ff1_warm_exit_step_ma = <200>;

		qcom,ffc2_normal_fastchg_ma = <750>;/*12C~35c*/
		qcom,ffc2_warm_fastchg_ma = <850>;	/* 35C ~ 40c */
		qcom,ffc2_temp_warm_decidegc = <350>;
		qcom,ffc2_temp_high_decidegc = <440>;
		qcom,ffc2_temp_low_decidegc = <120>;
		qcom,ffc2_exit_step_ma = <100>;
		qcom,ffc2_warm_exit_step_ma = <100>;

		qcom,ffc_normal_vfloat_sw_limit = <4495>;
		qcom,ffc_temp_normal_vfloat_mv = <4600>;
		qcom,ffc_normal_vfloat_over_sw_limit = <4600>;
		qcom,ffc_warm_vfloat_sw_limit = <4495>;

		qcom,ffc2_normal_vfloat_sw_limit = <4495>;
		qcom,ffc2_temp_normal_vfloat_mv = <4600>;
		qcom,ffc2_normal_vfloat_over_sw_limit = <4600>;
		qcom,ffc2_warm_vfloat_sw_limit = <4495>;


		qcom,default_iterm_ma = <302>;
		qcom,default_temp_normal_fastchg_current_ma = <2200>;
		qcom,default_normal_vfloat_sw_limit = <4415>;
		qcom,default_temp_normal_vfloat_mv = <4465>;
		qcom,default_normal_vfloat_over_sw_limit = <4475>;
		qcom,default_temp_little_cool_fastchg_current_ma = <2200>;
		qcom,default_little_cool_vfloat_sw_limit = <4415>;
		qcom,default_temp_little_cool_vfloat_mv = <4465>;
		qcom,default_little_cool_vfloat_over_sw_limit = <4475>;

		//for PD9V or QC9V
		qcom,vbatt_pdqc_to_5v_thr = <4500>;
		qcom,vbatt_pdqc_to_9v_thr = <4500>;

		//for control:
		qcom,cc_safeguard_enable;
		//qcom,suspend_after_full;
		qcom,check_batt_full_by_sw;
		qcom,chg_ctrl_by_lcd;
		qcom,dcp_screen_off_limit_switch;
		qcom,chg_ctrl_by_camera;
		qcom,chg_ctrl_by_calling;
		qcom,sw_vfloat_over_protect_enable;
		qcom,usbtemp_dischg_by_platpmic;
		qcom,support_usbtemp_protect_v2;
		qcom,ffc_support;
		qcom,chargerid_vol_disable;
		qcom,support_ntc_01c_precision;
		qcom,voocphy_support = <2>;
		//qcom,external_authenticate;
		qcom,chargerid_support;
		qcom,vooc_show_ui_soc_decimal;
		qcom,ui_soc_decimal_speedmin = <20>;//2A
		qcom,ccdetect_by_wd0;
		qcom,hvdcp_disabled; //turn off hvdcp func for doki
		//GPIO config:
		qcom,chargerid_switch-gpio = <&ap_gpio 175 0x00>;
		qcom,dischg-gpio = <&ap_gpio 11 0x00>;
		//qcom,ccdetect-gpio = <&ap_gpio 3 0x00>;
		qcom,support_abnormal_adapter;

		qcom,vooc-max-input-volt-support = <11000>;     //11V
		qcom,vooc-max-input-current-support = <4100>;   //4.1A

		oplus,support_hot_enter_kpoc;
		oplus,usbtemp_charging_current_limit = <2000>;
		oplus,poweroff_high_batt_temp = <720>;
		oplus,poweroff_emergency_batt_temp = <770>;
		oplus,usbtemp_batt_temp_over_hot = <60>;
		oplus,usbtemp_temp_gap_with_batt_temp_in_over_hot = <15>;
		qcom,external_gauge;
		qcom,smart_chg_soh_support;
		oplus,eco_common_support_region_list = <0x44>;
	};
};

&sc8547charger {
	battery2 {
		qcom,copycat_vooc_support;
		qcom,external_gauge_support;
		/*qcom,voocphy_dual_cp_support;*/
		qcom,slave_cp_enable_thr = <1900>;		//2000-100mA
		qcom,slave_cp_disable_thr_high = <1600>;	//1500+100mA
		qcom,voocphy_current_default = <41>;

		qcom,svooc_cool_down_current_limit = <82 20 20 24 30 34 40 44 50 54 60 64 70 74 80>;
		qcom,vooc_cool_down_current_limit = <30 20 20 20 30 30 30 30 30 30 30 30 30 30 30>;
		qcom,abnormal_adapter_current = <41 41 40 40 30 30 20 20>;

		qcom,vooc_multistep_initial_batt_temp = <1000>;

		qcom,vooc_strategy_normal_current = <100>;
		qcom,vooc_normal_to_little_cool_current = <100>;
		qcom,vooc_batt_over_high_temp = <510>;

		qcom,vooc-low-temp = <0>;
		qcom,vooc-high-temp = <500>;
		qcom,vooc-low-soc = <0>;
		qcom,vooc-high-soc = <90>;
		qcom,vooc-warm-allow-vol = <4000>;
		qcom,vooc-warm-allow-soc = <50>;

		qcom,vooc_little_cold_temp = <50>;
		qcom,vooc_cool_temp = <120>;
		qcom,vooc_little_cool_temp = <200>;
		qcom,vooc_normal_low_temp = <350>;
		qcom,vooc-normal-high-temp = <440>;

		qcom,vooc_strategy1_batt_high_temp0 = <400>;
		qcom,vooc_strategy1_batt_high_temp1 = <420>;
		qcom,vooc_strategy1_batt_high_temp2 = <430>;
		qcom,vooc_strategy1_batt_low_temp2 = <420>;
		qcom,vooc_strategy1_batt_low_temp1 = <410>;
		qcom,vooc_strategy1_batt_low_temp0 = <390>;

		qcom,vooc_strategy1_high_current0 = <50>;
		qcom,vooc_strategy1_high_current1 = <40>;
		qcom,vooc_strategy1_high_current2 = <20>;
		qcom,vooc_strategy1_low_current2 = <40>;
		qcom,vooc_strategy1_low_current1 = <50>;
		qcom,vooc_strategy1_low_current0 = <60>;

		qcom,voocphy_freq_mincore = <1800000>;
		qcom,voocphy_freq_midcore = <1800000>;
		qcom,voocphy_freq_maxcore = <1800000>;
		qcom,voocphy_current_change_timeout = <100>;

		oplus,workaround_for_100w;

		qcom,voocphy_ibat_over_current = <8500>;
		qcom,voocphy_svooc_cp_max_ibus = <4500>;
		qcom,voocphy_vooc_cp_max_ibus = <3500>;
		qcom,voocphy_cp_max_ibus = <4500>;

		qcom,vooc_little_cold_full_voltage = <4150>;
		qcom,vooc_cool_full_voltage = <4500>;
		qcom,vooc_warm_full_voltage = <4130>;
		qcom,vooc_1time_full_voltage = <4500>;
		qcom,vooc_ntime_full_voltage = <4500>;
		qcom,low_curr_full_t1 = <120>;
		qcom,low_curr_full_t2 = <350>;
		qcom,low_curr_full_t3 = <440>;
		qcom,range1_low_curr_full = <750 4500
						705 4495
						660 4480
						615 4470
						570 4460>;
		qcom,range2_low_curr_full = <850 4500
						805 4495
						760 4480
						715 4470
						670 4460>;

		svooc_batt_sys_curve = <0 1 0 1 0 0 0	// 4000mA
					1 1 1 1 0 0 0	// 4604mV
					0 0 1 1 0 1 0	// 2600mA
					1 1 1 1 0 0 0	// 4604mV
					0 0 0 1 0 1 1	// 1100mA
					1 1 1 1 0 0 0>;	// 4604mV

		vooc_batt_sys_curve =  <0 1 0 1 0 0 0	// 4000mA
					1 1 1 1 0 0 0	// 4604mV
					0 0 1 1 0 1 0	// 2600mA
					1 1 1 1 0 0 0	// 4604mV
					0 0 0 1 0 1 1	// 1100mA
					1 1 1 1 0 0 0>;	// 4604mV

		svooc_charge_strategy {
			strategy_soc_0_to_50 {
				strategy_temp_little_cold =	<4140 13 0 0 0
								 4150 10 1 0 0>;
				strategy_temp_cool =	<4150 22 0 0 0
								 4460 22 0 0 0
								 4460 20 0 0 0
								 4460 15 0 0 0
								 4490 13 0 0 0
								 4500 10 1 0 0>;
				strategy_temp_little_cool =	<4150 22 0 0 0
								 4460 22 0 0 0
								 4460 20 0 0 0
								 4460 15 0 0 0
								 4490 13 0 0 0
								 4500 10 1 0 0>;
				strategy_temp_normal_low =	<4150 41 0 60 0
								 4150 30 0 1200 0
								 4230 27 0 0 0
								 4230 25 0 1200 0
								 4460 22 0 0 0
								 4460 20 0 0 0
								 4460 15 0 0 0
								 4490 13 0 0 0
								 4500 10 1 0 0>;
				strategy_temp_normal_high =	<4150 41 0 60 0
								 4150 30 0 1200 0
								 4230 27 0 0 0
								 4230 25 0 1200 0
								 4460 22 0 0 0
								 4460 20 0 0 0
								 4460 15 0 0 0
								 4490 13 0 0 0
								 4500 10 1 0 0>;
				strategy_temp_warm = <4120 16 0 0 0
								 4120 15 0 0 0
								 4130 10 1 0 0>;
			};

			strategy_soc_50_to_75 {
				strategy_temp_little_cold =	<4150 10 1 0 0>;
				strategy_temp_cool =	<4460 15 0 0 0
								 4490 13 0 0 0
								 4500 10 1 0 0>;
				strategy_temp_little_cool =	<4460 20 0 0 0
								 4460 15 0 0 0
								 4490 13 0 0 0
								 4500 10 1 0 0>;
				strategy_temp_normal_low =	<4230 25 0 0 0
								 4460 22 0 0 0
								 4460 20 0 0 0
								 4460 15 0 0 0
								 4490 13 0 0 0
								 4500 10 1 0 0>;
				strategy_temp_normal_high =	<4230 25 0 0 0
								 4460 22 0 0 0
								 4460 20 0 0 0
								 4460 15 0 0 0
								 4490 13 0 0 0
								 4500 10 1 0 0>;
				strategy_temp_warm = <4130 15 1 0 0>;
			};

			strategy_soc_75_to_85 {
				strategy_temp_little_cold =	<4150 10 1 0 0>;
				strategy_temp_cool =	<4500 10 1 0 0>;
				strategy_temp_little_cool =	<4460 15 0 0 0
								 4490 13 0 0 0
								 4500 10 1 0 0>;
				strategy_temp_normal_low =	<4460 15 0 0 0
								 4490 13 0 0 0
								 4500 10 1 0 0>;
				strategy_temp_normal_high =	<4460 15 0 0 0
								 4490 13 0 0 0
								 4500 10 1 0 0>;
				strategy_temp_warm = <4130 15 1 0 0>;
			};

			strategy_soc_85_to_90 {
				strategy_temp_little_cold =	<4150 10 1 0 0>;
				strategy_temp_cool =		<4500 10 1 0 0>;
				strategy_temp_little_cool =	<4500 10 1 0 0>;
				strategy_temp_normal_low =	<4500 10 1 0 0>;
				strategy_temp_normal_high =	<4500 10 1 0 0>;
				strategy_temp_warm = 		<4130 15 1 0 0>;
			};
		};

		vooc_charge_strategy {
			strategy_soc_0_to_50 {
				strategy_temp_little_cold =	<4140 26 0 0 0
								 4150 20 1 0 0>;			/*0-5C*/
				strategy_temp_cool =	<4460 30 0 0 0
								 4490 26 0 0 0
								 4500 20 1 0 0>;			/*5-12C*/
				strategy_temp_little_cool =	<4460 30 0 0 0
								 4490 26 0 0 0
								 4500 20 1 0 0>;			/*12-20C*/
				strategy_temp_normal_low =	<4460 30 0 0 0
								 4490 26 0 0 0
								 4500 20 1 0 0>;			/*20-35C*/
				strategy_temp_normal_high =	<4460 30 0 0 0
								 4490 26 0 0 0
								 4500 20 1 0 0>;			/*35C-44C*/
				strategy_temp_warm =		<4120 30 0 0 0
								 4130 20 1 0 0>;
			};

			strategy_soc_50_to_75 {
				strategy_temp_little_cold =	<4150 20 1 0 0>;
				strategy_temp_cool =	<4460 30 0 0 0
								 4490 26 0 0 0
								 4500 20 1 0 0>;
				strategy_temp_little_cool =	<4460 30 0 0 0
								 4490 26 0 0 0
								 4500 20 1 0 0>;
				strategy_temp_normal_low =	<4460 30 0 0 0
								 4490 26 0 0 0
								 4500 20 1 0 0>;
				strategy_temp_normal_high =	<4460 30 0 0 0
								 4490 26 0 0 0
								 4500 20 1 0 0>;
				strategy_temp_warm = <4130 30 1 0 0>;
			};

			strategy_soc_75_to_85 {
				strategy_temp_little_cold =	<4150 20 1 0 0>;
				strategy_temp_cool =	<4500 20 1 0 0>;
				strategy_temp_little_cool =	<4460 30 0 0 0
								 4490 26 0 0 0
								 4500 20 1 0 0>;
				strategy_temp_normal_low =	<4460 30 0 0 0
								 4490 26 0 0 0
								 4500 20 1 0 0>;
				strategy_temp_normal_high =	<4460 30 0 0 0
								 4490 26 0 0 0
								 4500 20 1 0 0>;
				strategy_temp_warm = <4130 30 1 0 0>;
			};

			strategy_soc_85_to_90 {
				strategy_temp_little_cold =	<4150 20 1 0 0>;
				strategy_temp_cool =		<4500 20 1 0 0>;
				strategy_temp_little_cool =	<4500 20 1 0 0>;
				strategy_temp_normal_low =	<4500 20 1 0 0>;
				strategy_temp_normal_high =	<4500 20 1 0 0>;
				strategy_temp_warm = 		<4130 30 1 0 0>;
			};
		};
	};
};

&sy6542charger {
	battery2 {
		qcom,copycat_vooc_support;
		qcom,external_gauge_support;
		/*qcom,voocphy_dual_cp_support;*/
		qcom,slave_cp_enable_thr = <1900>;		//2000-100mA
		qcom,slave_cp_disable_thr_high = <1600>;	//1500+100mA
		qcom,voocphy_current_default = <41>;

		qcom,svooc_cool_down_current_limit = <82 20 20 24 30 34 40 44 50 54 60 64 70 74 80>;
		qcom,vooc_cool_down_current_limit = <30 20 20 20 30 30 30 30 30 30 30 30 30 30 30>;
		qcom,abnormal_adapter_current = <41 41 40 40 30 30 20 20>;

		qcom,vooc_multistep_initial_batt_temp = <1000>;

		qcom,vooc_strategy_normal_current = <100>;
		qcom,vooc_normal_to_little_cool_current = <100>;
		qcom,vooc_batt_over_high_temp = <510>;

		qcom,vooc-low-temp = <0>;
		qcom,vooc-high-temp = <500>;
		qcom,vooc-low-soc = <0>;
		qcom,vooc-high-soc = <90>;
		qcom,vooc-warm-allow-vol = <4000>;
		qcom,vooc-warm-allow-soc = <50>;

		qcom,vooc_little_cold_temp = <50>;
		qcom,vooc_cool_temp = <120>;
		qcom,vooc_little_cool_temp = <200>;
		qcom,vooc_normal_low_temp = <350>;
		qcom,vooc-normal-high-temp = <440>;

		qcom,vooc_strategy1_batt_high_temp0 = <400>;
		qcom,vooc_strategy1_batt_high_temp1 = <420>;
		qcom,vooc_strategy1_batt_high_temp2 = <430>;
		qcom,vooc_strategy1_batt_low_temp2 = <420>;
		qcom,vooc_strategy1_batt_low_temp1 = <410>;
		qcom,vooc_strategy1_batt_low_temp0 = <390>;

		qcom,vooc_strategy1_high_current0 = <50>;
		qcom,vooc_strategy1_high_current1 = <40>;
		qcom,vooc_strategy1_high_current2 = <20>;
		qcom,vooc_strategy1_low_current2 = <40>;
		qcom,vooc_strategy1_low_current1 = <50>;
		qcom,vooc_strategy1_low_current0 = <60>;

		qcom,voocphy_freq_mincore = <1800000>;
		qcom,voocphy_freq_midcore = <1800000>;
		qcom,voocphy_freq_maxcore = <1800000>;
		qcom,voocphy_current_change_timeout = <100>;

		oplus,workaround_for_100w;

		qcom,voocphy_ibat_over_current = <8500>;
		qcom,voocphy_svooc_cp_max_ibus = <4500>;
		qcom,voocphy_vooc_cp_max_ibus = <3500>;
		qcom,voocphy_cp_max_ibus = <4500>;

		qcom,vooc_little_cold_full_voltage = <4150>;
		qcom,vooc_cool_full_voltage = <4500>;
		qcom,vooc_warm_full_voltage = <4130>;
		qcom,vooc_1time_full_voltage = <4500>;
		qcom,vooc_ntime_full_voltage = <4500>;
		qcom,low_curr_full_t1 = <120>;
		qcom,low_curr_full_t2 = <350>;
		qcom,low_curr_full_t3 = <440>;
		qcom,range1_low_curr_full = <750 4500
						705 4495
						660 4480
						615 4470
						570 4460>;
		qcom,range2_low_curr_full = <850 4500
						805 4495
						760 4480
						715 4470
						670 4460>;

		svooc_batt_sys_curve = <0 1 0 1 0 0 0	// 4000mA
					1 1 1 1 0 0 0	// 4604mV
					0 0 1 1 0 1 0	// 2600mA
					1 1 1 1 0 0 0	// 4604mV
					0 0 0 1 0 1 1	// 1100mA
					1 1 1 1 0 0 0>;	// 4604mV

		vooc_batt_sys_curve =  <0 1 0 1 0 0 0	// 4000mA
					1 1 1 1 0 0 0	// 4604mV
					0 0 1 1 0 1 0	// 2600mA
					1 1 1 1 0 0 0	// 4604mV
					0 0 0 1 0 1 1	// 1100mA
					1 1 1 1 0 0 0>;	// 4604mV

		svooc_charge_strategy {
			strategy_soc_0_to_50 {
				strategy_temp_little_cold =	<4140 13 0 0 0
								 4150 10 1 0 0>;
				strategy_temp_cool =	<4150 22 0 0 0
								 4460 22 0 0 0
								 4460 20 0 0 0
								 4460 15 0 0 0
								 4490 13 0 0 0
								 4500 10 1 0 0>;
				strategy_temp_little_cool =	<4150 22 0 0 0
								 4460 22 0 0 0
								 4460 20 0 0 0
								 4460 15 0 0 0
								 4490 13 0 0 0
								 4500 10 1 0 0>;
				strategy_temp_normal_low =	<4150 41 0 60 0
								 4150 30 0 1200 0
								 4230 27 0 0 0
								 4230 25 0 1200 0
								 4460 22 0 0 0
								 4460 20 0 0 0
								 4460 15 0 0 0
								 4490 13 0 0 0
								 4500 10 1 0 0>;
				strategy_temp_normal_high =	<4150 41 0 60 0
								 4150 30 0 1200 0
								 4230 27 0 0 0
								 4230 25 0 1200 0
								 4460 22 0 0 0
								 4460 20 0 0 0
								 4460 15 0 0 0
								 4490 13 0 0 0
								 4500 10 1 0 0>;
				strategy_temp_warm = <4120 16 0 0 0
								 4120 15 0 0 0
								 4130 10 1 0 0>;
			};

			strategy_soc_50_to_75 {
				strategy_temp_little_cold =	<4150 10 1 0 0>;
				strategy_temp_cool =	<4460 15 0 0 0
								 4490 13 0 0 0
								 4500 10 1 0 0>;
				strategy_temp_little_cool =	<4460 20 0 0 0
								 4460 15 0 0 0
								 4490 13 0 0 0
								 4500 10 1 0 0>;
				strategy_temp_normal_low =	<4230 25 0 0 0
								 4460 22 0 0 0
								 4460 20 0 0 0
								 4460 15 0 0 0
								 4490 13 0 0 0
								 4500 10 1 0 0>;
				strategy_temp_normal_high =	<4230 25 0 0 0
								 4460 22 0 0 0
								 4460 20 0 0 0
								 4460 15 0 0 0
								 4490 13 0 0 0
								 4500 10 1 0 0>;
				strategy_temp_warm = <4130 15 1 0 0>;
			};

			strategy_soc_75_to_85 {
				strategy_temp_little_cold =	<4150 10 1 0 0>;
				strategy_temp_cool =	<4500 10 1 0 0>;
				strategy_temp_little_cool =	<4460 15 0 0 0
								 4490 13 0 0 0
								 4500 10 1 0 0>;
				strategy_temp_normal_low =	<4460 15 0 0 0
								 4490 13 0 0 0
								 4500 10 1 0 0>;
				strategy_temp_normal_high =	<4460 15 0 0 0
								 4490 13 0 0 0
								 4500 10 1 0 0>;
				strategy_temp_warm = <4130 15 1 0 0>;
			};

			strategy_soc_85_to_90 {
				strategy_temp_little_cold =	<4150 10 1 0 0>;
				strategy_temp_cool =		<4500 10 1 0 0>;
				strategy_temp_little_cool =	<4500 10 1 0 0>;
				strategy_temp_normal_low =	<4500 10 1 0 0>;
				strategy_temp_normal_high =	<4500 10 1 0 0>;
				strategy_temp_warm = 		<4130 15 1 0 0>;
			};
		};

		vooc_charge_strategy {
			strategy_soc_0_to_50 {
				strategy_temp_little_cold =	<4140 26 0 0 0
								 4150 20 1 0 0>;			/*0-5C*/
				strategy_temp_cool =	<4460 30 0 0 0
								 4490 26 0 0 0
								 4500 20 1 0 0>;			/*5-12C*/
				strategy_temp_little_cool =	<4460 30 0 0 0
								 4490 26 0 0 0
								 4500 20 1 0 0>;			/*12-20C*/
				strategy_temp_normal_low =	<4460 30 0 0 0
								 4490 26 0 0 0
								 4500 20 1 0 0>;			/*20-35C*/
				strategy_temp_normal_high =	<4460 30 0 0 0
								 4490 26 0 0 0
								 4500 20 1 0 0>;			/*35C-44C*/
				strategy_temp_warm =		<4120 30 0 0 0
								 4130 20 1 0 0>;
			};

			strategy_soc_50_to_75 {
				strategy_temp_little_cold =	<4150 20 1 0 0>;
				strategy_temp_cool =	<4460 30 0 0 0
								 4490 26 0 0 0
								 4500 20 1 0 0>;
				strategy_temp_little_cool =	<4460 30 0 0 0
								 4490 26 0 0 0
								 4500 20 1 0 0>;
				strategy_temp_normal_low =	<4460 30 0 0 0
								 4490 26 0 0 0
								 4500 20 1 0 0>;
				strategy_temp_normal_high =	<4460 30 0 0 0
								 4490 26 0 0 0
								 4500 20 1 0 0>;
				strategy_temp_warm = <4130 30 1 0 0>;
			};

			strategy_soc_75_to_85 {
				strategy_temp_little_cold =	<4150 20 1 0 0>;
				strategy_temp_cool =	<4500 20 1 0 0>;
				strategy_temp_little_cool =	<4460 30 0 0 0
								 4490 26 0 0 0
								 4500 20 1 0 0>;
				strategy_temp_normal_low =	<4460 30 0 0 0
								 4490 26 0 0 0
								 4500 20 1 0 0>;
				strategy_temp_normal_high =	<4460 30 0 0 0
								 4490 26 0 0 0
								 4500 20 1 0 0>;
				strategy_temp_warm = <4130 30 1 0 0>;
			};

			strategy_soc_85_to_90 {
				strategy_temp_little_cold =	<4150 20 1 0 0>;
				strategy_temp_cool =		<4500 20 1 0 0>;
				strategy_temp_little_cool =	<4500 20 1 0 0>;
				strategy_temp_normal_low =	<4500 20 1 0 0>;
				strategy_temp_normal_high =	<4500 20 1 0 0>;
				strategy_temp_warm = 		<4130 30 1 0 0>;
			};
		};
	};
};

&sc8547dcharger {
	battery2 {
		qcom,copycat_vooc_support;
		qcom,external_gauge_support;
		/*qcom,voocphy_dual_cp_support;*/
		qcom,slave_cp_enable_thr = <1900>;		//2000-100mA
		qcom,slave_cp_disable_thr_high = <1600>;	//1500+100mA
		qcom,voocphy_current_default = <41>;

		qcom,svooc_cool_down_current_limit = <82 20 20 24 30 34 40 44 50 54 60 64 70 74 80>;
		qcom,vooc_cool_down_current_limit = <30 20 20 20 30 30 30 30 30 30 30 30 30 30 30>;
		qcom,abnormal_adapter_current = <41 41 40 40 30 30 20 20>;

		qcom,vooc_multistep_initial_batt_temp = <1000>;

		qcom,vooc_strategy_normal_current = <100>;
		qcom,vooc_normal_to_little_cool_current = <100>;
		qcom,vooc_batt_over_high_temp = <510>;

		qcom,vooc-low-temp = <0>;
		qcom,vooc-high-temp = <500>;
		qcom,vooc-low-soc = <0>;
		qcom,vooc-high-soc = <90>;
		qcom,vooc-warm-allow-vol = <4000>;
		qcom,vooc-warm-allow-soc = <50>;

		qcom,vooc_little_cold_temp = <50>;
		qcom,vooc_cool_temp = <120>;
		qcom,vooc_little_cool_temp = <200>;
		qcom,vooc_normal_low_temp = <350>;
		qcom,vooc-normal-high-temp = <440>;

		qcom,vooc_strategy1_batt_high_temp0 = <400>;
		qcom,vooc_strategy1_batt_high_temp1 = <420>;
		qcom,vooc_strategy1_batt_high_temp2 = <430>;
		qcom,vooc_strategy1_batt_low_temp2 = <420>;
		qcom,vooc_strategy1_batt_low_temp1 = <410>;
		qcom,vooc_strategy1_batt_low_temp0 = <390>;

		qcom,vooc_strategy1_high_current0 = <50>;
		qcom,vooc_strategy1_high_current1 = <40>;
		qcom,vooc_strategy1_high_current2 = <20>;
		qcom,vooc_strategy1_low_current2 = <40>;
		qcom,vooc_strategy1_low_current1 = <50>;
		qcom,vooc_strategy1_low_current0 = <60>;

		qcom,voocphy_freq_mincore = <1800000>;
		qcom,voocphy_freq_midcore = <1800000>;
		qcom,voocphy_freq_maxcore = <1800000>;
		qcom,voocphy_current_change_timeout = <100>;

		oplus,workaround_for_100w;

		qcom,voocphy_ibat_over_current = <8500>;
		qcom,voocphy_svooc_cp_max_ibus = <4500>;
		qcom,voocphy_vooc_cp_max_ibus = <3500>;
		qcom,voocphy_cp_max_ibus = <4500>;

		qcom,vooc_little_cold_full_voltage = <4150>;
		qcom,vooc_cool_full_voltage = <4500>;
		qcom,vooc_warm_full_voltage = <4130>;
		qcom,vooc_1time_full_voltage = <4500>;
		qcom,vooc_ntime_full_voltage = <4500>;
		qcom,low_curr_full_t1 = <120>;
		qcom,low_curr_full_t2 = <350>;
		qcom,low_curr_full_t3 = <440>;
		qcom,range1_low_curr_full = <750 4500
						705 4495
						660 4480
						615 4470
						570 4460>;
		qcom,range2_low_curr_full = <850 4500
						805 4495
						760 4480
						715 4470
						670 4460>;

		svooc_batt_sys_curve = <0 1 0 1 0 0 0	// 4000mA
					1 1 1 1 0 0 0	// 4604mV
					0 0 1 1 0 1 0	// 2600mA
					1 1 1 1 0 0 0	// 4604mV
					0 0 0 1 0 1 1	// 1100mA
					1 1 1 1 0 0 0>;	// 4604mV

		vooc_batt_sys_curve =  <0 1 0 1 0 0 0	// 4000mA
					1 1 1 1 0 0 0	// 4604mV
					0 0 1 1 0 1 0	// 2600mA
					1 1 1 1 0 0 0	// 4604mV
					0 0 0 1 0 1 1	// 1100mA
					1 1 1 1 0 0 0>;	// 4604mV

		svooc_charge_strategy {
			strategy_soc_0_to_50 {
				strategy_temp_little_cold =	<4140 13 0 0 0
								 4150 10 1 0 0>;
				strategy_temp_cool =	<4150 22 0 0 0
								 4460 22 0 0 0
								 4460 20 0 0 0
								 4460 15 0 0 0
								 4490 13 0 0 0
								 4500 10 1 0 0>;
				strategy_temp_little_cool =	<4150 22 0 0 0
								 4460 22 0 0 0
								 4460 20 0 0 0
								 4460 15 0 0 0
								 4490 13 0 0 0
								 4500 10 1 0 0>;
				strategy_temp_normal_low =	<4150 41 0 60 0
								 4150 30 0 1200 0
								 4230 27 0 0 0
								 4230 25 0 1200 0
								 4460 22 0 0 0
								 4460 20 0 0 0
								 4460 15 0 0 0
								 4490 13 0 0 0
								 4500 10 1 0 0>;
				strategy_temp_normal_high =	<4150 41 0 60 0
								 4150 30 0 1200 0
								 4230 27 0 0 0
								 4230 25 0 1200 0
								 4460 22 0 0 0
								 4460 20 0 0 0
								 4460 15 0 0 0
								 4490 13 0 0 0
								 4500 10 1 0 0>;
				strategy_temp_warm = <4120 16 0 0 0
								 4120 15 0 0 0
								 4130 10 1 0 0>;
			};

			strategy_soc_50_to_75 {
				strategy_temp_little_cold =	<4150 10 1 0 0>;
				strategy_temp_cool =	<4460 15 0 0 0
								 4490 13 0 0 0
								 4500 10 1 0 0>;
				strategy_temp_little_cool =	<4460 20 0 0 0
								 4460 15 0 0 0
								 4490 13 0 0 0
								 4500 10 1 0 0>;
				strategy_temp_normal_low =	<4230 25 0 0 0
								 4460 22 0 0 0
								 4460 20 0 0 0
								 4460 15 0 0 0
								 4490 13 0 0 0
								 4500 10 1 0 0>;
				strategy_temp_normal_high =	<4230 25 0 0 0
								 4460 22 0 0 0
								 4460 20 0 0 0
								 4460 15 0 0 0
								 4490 13 0 0 0
								 4500 10 1 0 0>;
				strategy_temp_warm = <4130 15 1 0 0>;
			};

			strategy_soc_75_to_85 {
				strategy_temp_little_cold =	<4150 10 1 0 0>;
				strategy_temp_cool =	<4500 10 1 0 0>;
				strategy_temp_little_cool =	<4460 15 0 0 0
								 4490 13 0 0 0
								 4500 10 1 0 0>;
				strategy_temp_normal_low =	<4460 15 0 0 0
								 4490 13 0 0 0
								 4500 10 1 0 0>;
				strategy_temp_normal_high =	<4460 15 0 0 0
								 4490 13 0 0 0
								 4500 10 1 0 0>;
				strategy_temp_warm = <4130 15 1 0 0>;
			};

			strategy_soc_85_to_90 {
				strategy_temp_little_cold =	<4150 10 1 0 0>;
				strategy_temp_cool =		<4500 10 1 0 0>;
				strategy_temp_little_cool =	<4500 10 1 0 0>;
				strategy_temp_normal_low =	<4500 10 1 0 0>;
				strategy_temp_normal_high =	<4500 10 1 0 0>;
				strategy_temp_warm = 		<4130 15 1 0 0>;
			};
		};

		vooc_charge_strategy {
			strategy_soc_0_to_50 {
				strategy_temp_little_cold =	<4140 26 0 0 0
								 4150 20 1 0 0>;			/*0-5C*/
				strategy_temp_cool =	<4460 30 0 0 0
								 4490 26 0 0 0
								 4500 20 1 0 0>;			/*5-12C*/
				strategy_temp_little_cool =	<4460 30 0 0 0
								 4490 26 0 0 0
								 4500 20 1 0 0>;			/*12-20C*/
				strategy_temp_normal_low =	<4460 30 0 0 0
								 4490 26 0 0 0
								 4500 20 1 0 0>;			/*20-35C*/
				strategy_temp_normal_high =	<4460 30 0 0 0
								 4490 26 0 0 0
								 4500 20 1 0 0>;			/*35C-44C*/
				strategy_temp_warm =		<4120 30 0 0 0
								 4130 20 1 0 0>;
			};

			strategy_soc_50_to_75 {
				strategy_temp_little_cold =	<4150 20 1 0 0>;
				strategy_temp_cool =	<4460 30 0 0 0
								 4490 26 0 0 0
								 4500 20 1 0 0>;
				strategy_temp_little_cool =	<4460 30 0 0 0
								 4490 26 0 0 0
								 4500 20 1 0 0>;
				strategy_temp_normal_low =	<4460 30 0 0 0
								 4490 26 0 0 0
								 4500 20 1 0 0>;
				strategy_temp_normal_high =	<4460 30 0 0 0
								 4490 26 0 0 0
								 4500 20 1 0 0>;
				strategy_temp_warm = <4130 30 1 0 0>;
			};

			strategy_soc_75_to_85 {
				strategy_temp_little_cold =	<4150 20 1 0 0>;
				strategy_temp_cool =	<4500 20 1 0 0>;
				strategy_temp_little_cool =	<4460 30 0 0 0
								 4490 26 0 0 0
								 4500 20 1 0 0>;
				strategy_temp_normal_low =	<4460 30 0 0 0
								 4490 26 0 0 0
								 4500 20 1 0 0>;
				strategy_temp_normal_high =	<4460 30 0 0 0
								 4490 26 0 0 0
								 4500 20 1 0 0>;
				strategy_temp_warm = <4130 30 1 0 0>;
			};

			strategy_soc_85_to_90 {
				strategy_temp_little_cold =	<4150 20 1 0 0>;
				strategy_temp_cool =		<4500 20 1 0 0>;
				strategy_temp_little_cool =	<4500 20 1 0 0>;
				strategy_temp_normal_low =	<4500 20 1 0 0>;
				strategy_temp_normal_high =	<4500 20 1 0 0>;
				strategy_temp_warm = 		<4130 30 1 0 0>;
			};
		};
	};
};

&i2c2 {
	status = "okay";
	clock-frequency = <400000>;
	#address-cells = <1>;
	#size-cells = <0>;
	sgm41542:sgm41542@1A { //sy
		status = "okay";
		compatible = "oplus,sgm41542";
		reg = <0x1A>;
		interrupt-parent = <&ap_gpio>;
		interrupts = <133 0>;
		sgm41542-irq-gpio = <&ap_gpio 133 0>;
		//qcom-dpdm_switch = <&ap_gpio 167 0x00>;
		//dpdm-supply = <&usb2_phy0>;
		// qcom,slave_charger_enable-gpio = <&ap_gpio 12 0x00>;
		qcom,use_voocphy;
		qcom,vindpm_4V48;
		//pinctrl-names = "default";
		//pinctrl-0 = <&sgm41512_int_default>;
		vddvbus:otg-vbus {
			regulator-name = "vddvbus";
		};
 	};
};

&i2c3 {
    status = "okay";
    clock-frequency = <400000>;
    #address-cells = <1>;
    #size-cells = <0>;

    oplus_ext_gauge: bq27541-battery@55 {
        status = "okay";
        compatible = "oplus,bq27541-battery";
        reg = <0x55>;
		oplus,batt_nfg8011b;
		gauge_batt = "ATL_6000MA_4P48V";
		qcom,modify-soc-smooth;
		qcom,modify-soc-calibration;
		oplus,support_extern_cmd;
    };
};
